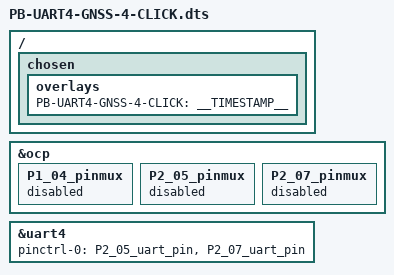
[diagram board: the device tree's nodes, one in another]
/*
 * Copyright (C) 2018 Robert Nelson <robertcnelson@gmail.com>
 *
 * This program is free software; you can redistribute it and/or modify
 * it under the terms of the GNU General Public License version 2 as
 * published by the Free Software Foundation.
 *
 * https://www.mikroe.com/gnss-4-click
 * https://download.mikroe.com/documents/add-on-boards/click/gnss-4/gnss4-click-schematic-v100.pdf
 */

/dts-v1/;
/plugin/;

#include <dt-bindings/gpio/gpio.h>
#include <dt-bindings/pinctrl/am33xx.h>
#include <dt-bindings/interrupt-controller/irq.h>

/ {
	/*
	 * Helper to show loaded overlays under: /proc/device-tree/chosen/overlays/
	 */
	fragment@0 {
		target-path="/";
		__overlay__ {

			chosen {
				overlays {
					PB-UART4-GNSS-4-CLICK = __TIMESTAMP__;
				};
			};
		};
	};

	/*
	 * Free up the pins used by the cape from the pinmux helpers.
	 */
	fragment@1 {
		target = <&ocp>;
		__overlay__ {
			P1_04_pinmux { status = "disabled"; };	/* gpio2_25 - RST */
			P2_05_pinmux { status = "disabled"; };	/* gpio0_30 - TXD */
			P2_07_pinmux { status = "disabled"; };	/* gpio0_31 - RXD */
		};
	};

	fragment@2 {
		target = <&uart4>;
		__overlay__ {
			status = "okay";
			pinctrl-names = "default";
			pinctrl-0 = <
				&P2_05_uart_pin
				&P2_07_uart_pin
			>;
		};
	};
};
